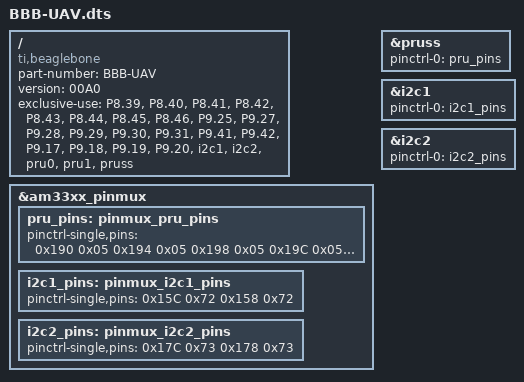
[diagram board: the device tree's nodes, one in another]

//~~~~~~~~~~~~~~~~~~~~~~~~~~~~~~~~~~~~~~~~
//  BBB-UAV.dts
//  Justin M Selfridge
//~~~~~~~~~~~~~~~~~~~~~~~~~~~~~~~~~~~~~~~~

/dts-v1/;
/plugin/;

/ {


    //--  Identification  --//
    compatible   = "ti,beaglebone", "ti,beaglebone-black";
    part-number  = "BBB-UAV";
    version      = "00A0";


    //--  Allocate hardware and pins  --//
    exclusive-use = 

        //--  RADIO  --//
        "P8.39",
        "P8.40",
        "P8.41",
        "P8.42",
        "P8.43",
        "P8.44",
        "P8.45",
        "P8.46",

        //--  SERVO  --//
        "P9.25",
        "P9.27",
        "P9.28",
        "P9.29",
        "P9.30",
        "P9.31",
        "P9.41",
        "P9.42",

/*        //--  SERIAL  --//
        "P8.37",
        "P8.38",
        "P9.11",
        "P9.13",
        "P9.21",
        "P9.22",
        "P9.24",
        "P9.26",
*/
        //--  I2C  --//
        "P9.17",
        "P9.18",
        "P9.19",
        "P9.20",

        //--  HARDWARE  --//
        //"uart1",
        //"uart2",
        //"uart4",
        //"uart5",
        "i2c1",
        "i2c2",
        "pru0",
        "pru1",
        "pruss";


    //--  Primary fragment  --//
    fragment@0 {
        target = <&am33xx_pinmux>;
        __overlay__ {

            //--  PRU pins  --//
            pru_pins: pinmux_pru_pins {
                pinctrl-single,pins = <

                    //-- PRU0: output to servo  --//
                    0x190  0x05      //  P9.31 | r30_00 | MODE 5  //
                    0x194  0x05	     //  P9.29 | r30_01 | MODE 5  //
                    0x198  0x05      //  P9.30 | r30_02 | MODE 5  //
                    0x19C  0x05      //  P9.28 | r30_03 | MODE 5  //
                    0x1A0  0x05      //  P9.42 | r30_04 | MODE 5  //
                    0x1A4  0x05	     //  P9.27 | r30_05 | MODE 5  //
                    0x1A8  0x05	     //  P9.41 | r30_06 | MODE 5  //
                    0x1AC  0x05      //  P9.25 | r30_07 | MODE 5  //
                    0x1B4  0x20      //  Enable P9.41  //
                    0x164  0x20	     //  Enable P9.42  //

                    //--  PRU1: input from radio  --//
                    0x0A0  0x26      //  P8.45 | r31_00 | MODE 6  //
                    0x0A4  0x26      //  P8.46 | r31_01 | MODE 6  //
                    0x0A8  0x26      //  P8.43 | r31_02 | MODE 6  //
                    0x0AC  0x26      //  P8.44 | r31_03 | MODE 6  //
                    0x0B0  0x26      //  P8.41 | r31_04 | MODE 6  //
                    0x0B4  0x26      //  P8.42 | r31_05 | MODE 6  //
                    0x0B8  0x26      //  P8.39 | r31_06 | MODE 6  //
                    0x0BC  0x26      //  P8.40 | r31_07 | MODE 6  //

                >;
            };

/*            //--  UART1 pins  --//
            uart1_pins: pinmux_uart1_pins {
                pinctrl-single,pins = <
                    0x184  0x20      //  P9.24 | UART1_TX | MODE 0  //
                    0x180  0x20      //  P9.26 | UART1_RX | MODE 0  //
                >;
            };
*/
/*            //--  UART2 pins  --//
            uart2_pins: pinmux_uart2_pins {
                pinctrl-single,pins = <
                    0x154  0x21      //  P9.21 | UART2_TX | MODE 1  //
                    0x150  0x21      //  P9.22 | UART2_RX | MODE 1  //
                >;
            };
*/
/*            //--  UART4 pins  --//
            uart4_pins: pinmux_uart4_pins {
                pinctrl-single,pins = <
                    0x074  0x26      //  P9.13 | UART4_TX | MODE 6  //
                    0x070  0x26      //  P9.11 | UART4_RX | MODE 6  //
                >;
            };
*/
/*            //--  UART5 pins  --//
            uart5_pins: pinmux_uart5_pins {
                pinctrl-single,pins = <
                    0x0C0  0x24      //  P8.37 | UART5_TX | MODE 4  //
                    0x0C4  0x24      //  P8.38 | UART5_RX | MODE 4  //
                >;
            };
*/
            //--  I2C1 pins  --//
            i2c1_pins: pinmux_i2c1_pins {
                pinctrl-single,pins = <
                    0x15C  0x72      //  P9.17 | I2C1_SCL | MODE 2  //
                    0x158  0x72      //  P9.18 | I2C1_SDA | MODE 2  //
                >;
            };

            //--  I2C2 pins  --//
            i2c2_pins: pinmux_i2c2_pins {
                pinctrl-single,pins = <
                    0x17C  0x73      //  P9.19 | I2C2_SCL | MODE 3  //
                    0x178  0x73      //  P9.20 | I2C2_SDA | MODE 3  //
                >;
            };

        };
    };


    //--  PRU  --//
    fragment@1 {
        target = <&pruss>;
        __overlay__ {
            status = "okay";
            pinctrl-names = "default";
            pinctrl-0 = <&pru_pins>;
        };
    };

/*    //--  UART1  --//
    fragment@2 {
        target = <&uart2>;
        __overlay__ {
            status = "okay";
            pinctrl-names = "default";
            pinctrl-0 = <&uart1_pins>;
        };
    };
*/
/*    //--  UART2  --//
    fragment@3 {
        target = <&uart3>;
        __overlay__ {
            status = "okay";
            pinctrl-names = "default";
            pinctrl-0 = <&uart2_pins>;
        };
    };
*/
/*    //--  UART4  --//
    fragment@4 {
        target = <&uart5>;
        __overlay__ {
            status = "okay";
            pinctrl-names = "default";
            pinctrl-0 = <&uart4_pins>;
        };
    };
*/
/*    //--  UART5  --//
    fragment@5 {
        target = <&uart6>;
        __overlay__ {
            status = "okay";
            pinctrl-names = "default";
            pinctrl-0 = <&uart5_pins>;
        };
    };
*/
    //--  I2C1  --//
    fragment@6 {
        target = <&i2c1>;
        __overlay__ {
            status = "okay";
            pinctrl-names = "default";
            pinctrl-0 = <&i2c1_pins>;
        };
    };

    //--  I2C2  --//
    fragment@7 {
        target = <&i2c2>;
        __overlay__ {
            status = "okay";
            pinctrl-names = "default";
            pinctrl-0 = <&i2c2_pins>;
        };
    };


};



